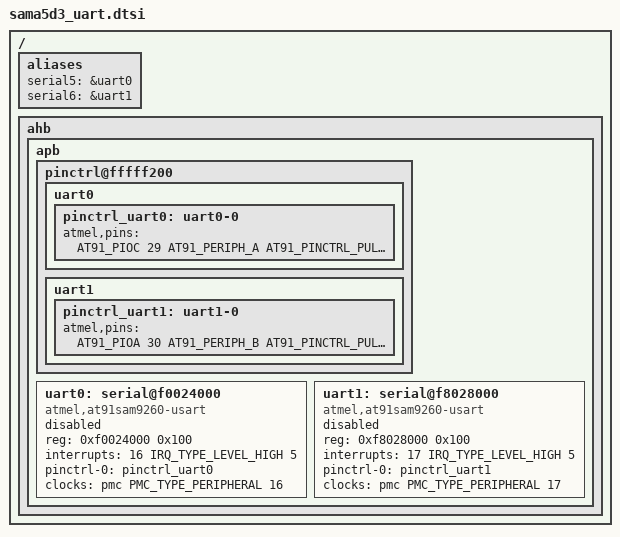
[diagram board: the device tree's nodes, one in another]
// SPDX-License-Identifier: GPL-2.0-only
/*
 * sama5d3_uart.dtsi - Device Tree Include file for SAMA5D3 SoC with
 * UART support
 *
 * Copyright (C) 2013 Boris BREZILLON <b.brezillon@overkiz.com>
 */

#include <dt-bindings/pinctrl/at91.h>
#include <dt-bindings/interrupt-controller/irq.h>
#include <dt-bindings/clock/at91.h>

/ {
	aliases {
		serial5 = &uart0;
		serial6 = &uart1;
	};

	ahb {
		apb {
			pinctrl@fffff200 {
				uart0 {
					pinctrl_uart0: uart0-0 {
						atmel,pins =
							<AT91_PIOC 29 AT91_PERIPH_A AT91_PINCTRL_PULL_UP	/* conflicts with PWMFI2, ISI_D8 */
							 AT91_PIOC 30 AT91_PERIPH_A AT91_PINCTRL_NONE>;	/* conflicts with ISI_PCK */
					};
				};

				uart1 {
					pinctrl_uart1: uart1-0 {
						atmel,pins =
							<AT91_PIOA 30 AT91_PERIPH_B AT91_PINCTRL_PULL_UP	/* conflicts with TWD0, ISI_VSYNC */
							 AT91_PIOA 31 AT91_PERIPH_B AT91_PINCTRL_NONE>;	/* conflicts with TWCK0, ISI_HSYNC */
					};
				};
			};

			uart0: serial@f0024000 {
				compatible = "atmel,at91sam9260-usart";
				reg = <0xf0024000 0x100>;
				interrupts = <16 IRQ_TYPE_LEVEL_HIGH 5>;
				pinctrl-names = "default";
				pinctrl-0 = <&pinctrl_uart0>;
				clocks = <&pmc PMC_TYPE_PERIPHERAL 16>;
				clock-names = "usart";
				status = "disabled";
			};

			uart1: serial@f8028000 {
				compatible = "atmel,at91sam9260-usart";
				reg = <0xf8028000 0x100>;
				interrupts = <17 IRQ_TYPE_LEVEL_HIGH 5>;
				pinctrl-names = "default";
				pinctrl-0 = <&pinctrl_uart1>;
				clocks = <&pmc PMC_TYPE_PERIPHERAL 17>;
				clock-names = "usart";
				status = "disabled";
			};
		};
	};
};
